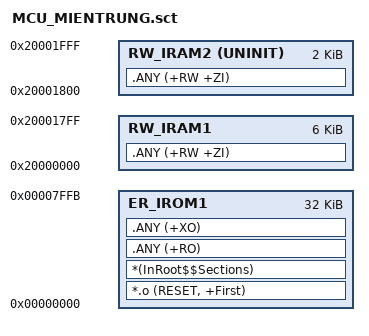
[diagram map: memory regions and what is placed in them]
; *************************************************************
; *** Scatter-Loading Description File generated by uVision ***
; *************************************************************

LR_IROM1 0x00000000 0x00007FFC  {    ; load region size_region
  ER_IROM1 0x00000000 0x00007FFC  {  ; load address = execution address
   *.o (RESET, +First)
   *(InRoot$$Sections)
   .ANY (+RO)
   .ANY (+XO)
  }
  RW_IRAM1 0x20000000 0x00001800  {  ; RW data
   .ANY (+RW +ZI)
  }
  RW_IRAM2 0x20001800 UNINIT 0x00000800  {
   .ANY (+RW +ZI)
  }
}

